# pse84 register map
Vendor: Infineon Technologies; Series: PSE84; File version: 1.0
CPU: CM33 r0p1, little endian, MPU, FPU, VTOR, 3 interrupt priority bits
Registers are 32-bit, read-write, reset 0x0 unless marked. A register's access mark holds for its fields unless they carry their own. Offsets are from the block's base; [hi:lo] are bit positions.

## MXNNLITE_2_0
Base 0x42D80000
0x04 WEIGHTSTREAMERBASEADDR
  [31:0] WEIGHTSTREAMERBASEADDR — Byte addresses, defines the address of the first dataset (first row, first col) programmable:configurable only when IP is enabled by SL_CTL bit. Do not update while a layer computation is active (BUSY_STATUS='1')! Updating during BUSY_STATUS='1' will cause unpredictable behavior.
0x08 WEIGHTSTREAMEROFFSET
  [16:0] WEIGHTSTREAMEROFFSET — Signed offset added to every weight programmable:configurable only when IP is enabled by SL_CTL bit. Do not update while a layer computation is active (BUSY_STATUS='1')! Updating during BUSY_STATUS='1' will cause unpredictable behavior.
0x0C WEIGHTSTREAMERKERNELCHANNELTIMESHEIGHTTIMESWIDTH
  [17:0] WEIGHTSTREAMERKERNELCHANNELTIMESHEIGHTTIMESWIDTH — Unsigned total number of kernel elements, disables Streamer, when last element reached. FSM updates this register as the number of nonzeroweights when sparsity is enabled, data is valid from bias streamer programmable:configurable only when IP is enabled by SL_CTL bit. Do not update while a layer computation is active (BUSY_STATUS='1')! Updating during BUSY_STATUS='1' will cause unpredictable behavior.
0x10 ACTIVATIONSTREAMERCHANNEL
  [16:0] ACTIVATIONSTREAMERCHANNEL — Unsigned number of elements in activation map per channel programmable:configurable only when IP is enabled by SL_CTL bit. Do not update while a layer computation is active (BUSY_STATUS='1')! Updating during BUSY_STATUS='1' will cause unpredictable behavior.
0x14 ACTIVATIONSTREAMERBASEADDR
  [31:0] ACTIVATIONSTREAMERBASEADDR — Byte addresses, defines the address of the first dataset (first row, first col) programmable:configurable only when IP is enabled by SL_CTL bit. Do not update while a layer computation is active (BUSY_STATUS='1')! Updating during BUSY_STATUS='1' will cause unpredictable behavior.
0x18 ACTIVATIONSTREAMEROFFSET
  [16:0] ACTIVATIONSTREAMEROFFSET — 9-bit or 17-bit signed offset added to fetch data programmable:configurable only when IP is enabled by SL_CTL bit. Do not update while a layer computation is active (BUSY_STATUS='1')! Updating during BUSY_STATUS='1' will cause unpredictable behavior.
0x1C ACTIVATIONSTREAMERKERNELCHANNELTIMESWIDTH
  [17:0] ACTIVATIONSTREAMERKERNELCHANNELTIMESWIDTH — Kernel channel times width (input assumed to be 2D row-minor or row/channel minor memory layout) programmable:configurable only when IP is enabled by SL_CTL bit. Do not update while a layer computation is active (BUSY_STATUS='1')! Updating during BUSY_STATUS='1' will cause unpredictable behavior.
0x20 ACTIVATIONSTREAMERKERNELHEIGHT
  [16:0] ACTIVATIONSTREAMERKERNELHEIGHT — Kernel height (input assumed to be 2D row-minor or row/channel minor memory layout) programmable:configurable only when IP is enabled by SL_CTL bit. Do not update while a layer computation is active (BUSY_STATUS='1')! Updating during BUSY_STATUS='1' will cause unpredictable behavior.
0x24 ACTIVATIONSTREAMERREPEATS
  [17:0] ACTIVATIONSTREAMERREPEATS — Numer of repeated fetches of kernel footprint in memory ( 1 will fetch once, 0 is invalid input) programmable:configurable only when IP is enabled by SL_CTL bit. Do not update while a layer computation is active (BUSY_STATUS='1')! Updating during BUSY_STATUS='1' will cause unpredictable behavior.
0x28 ACTIVATIONSTREAMERSTARTCOL
  [17:0] ACTIVATIONSTREAMERSTARTCOL — Signed start column to move kernel window over the activation map (col=0 & row=0 hits baseaddr) programmable:configurable only when IP is enabled by SL_CTL bit. Do not update while a layer computation is active (BUSY_STATUS='1')! Updating during BUSY_STATUS='1' will cause unpredictable behavior.
0x2C ACTIVATIONSTREAMERSTARTROW
  [17:0] ACTIVATIONSTREAMERSTARTROW — Signed start row to move kernel window over the activation map (col=0 & row=0 hits baseaddr) programmable:configurable only when IP is enabled by SL_CTL bit. Do not update while a layer computation is active (BUSY_STATUS='1')! Updating during BUSY_STATUS='1' will cause unpredictable behavior.
0x30 ACTIVATIONSTREAMERCHANNELTIMESWIDTH
  [16:0] ACTIVATIONSTREAMERCHANNELTIMESWIDTH — Unsigned number of elements in activation map per channel * width programmable:configurable only when IP is enabled by SL_CTL bit. Do not update while a layer computation is active (BUSY_STATUS='1')! Updating during BUSY_STATUS='1' will cause unpredictable behavior.
0x34 ACTIVATIONSTREAMERHEIGHT
  [16:0] ACTIVATIONSTREAMERHEIGHT — Unsigned number of elements in height in activation map till end of loop programmable:configurable only when IP is enabled by SL_CTL bit. Do not update while a layer computation is active (BUSY_STATUS='1')! Updating during BUSY_STATUS='1' will cause unpredictable behavior.
0x38 ACTIVATIONSTREAMERPADDING
  [15:0] ACTIVATIONSTREAMERPADVALUE — Defines signed values out of activation map programmable:configurable only when IP is enabled by SL_CTL bit. Do not update while a layer computation is active (BUSY_STATUS='1')! Updating during BUSY_STATUS='1' will cause unpredictable behavior.
0x3C ACTIVATIONSTREAMERSPARSITYMAPBASEADDR
  [31:0] ACTIVATIONSTREAMERSPARSITYMAPBASEADDR — Byte addresses, defines the address of start of sparsity bit(map) for sparse footprint fetch programmable:configurable only when IP is enabled by SL_CTL bit. Do not update while a layer computation is active (BUSY_STATUS='1')! Updating during BUSY_STATUS='1' will cause unpredictable behavior.
0x40 OUTSTREAMERBASEADDR
  [31:0] OUTSTREAMERBASEADDR — Byte addresses, defines the address of the first dataset (first row, first col) programmable:configurable only when IP is enabled by SL_CTL bit. Do not update while a layer computation is active (BUSY_STATUS='1')! Updating during BUSY_STATUS='1' will cause unpredictable behavior.
0x44 OUTSTREAMEROUTPUTOFFSET
  [16:0] OUTSTREAMEROUTPUTOFFSET — Signed offset added to the output activation. The outstreamer supports 8-bit output neuron. The configuration range is [-256, 255] programmable:configurable only when IP is enabled by SL_CTL bit. Do not update while a layer computation is active (BUSY_STATUS='1')! Updating during BUSY_STATUS='1' will cause unpredictable behavior.
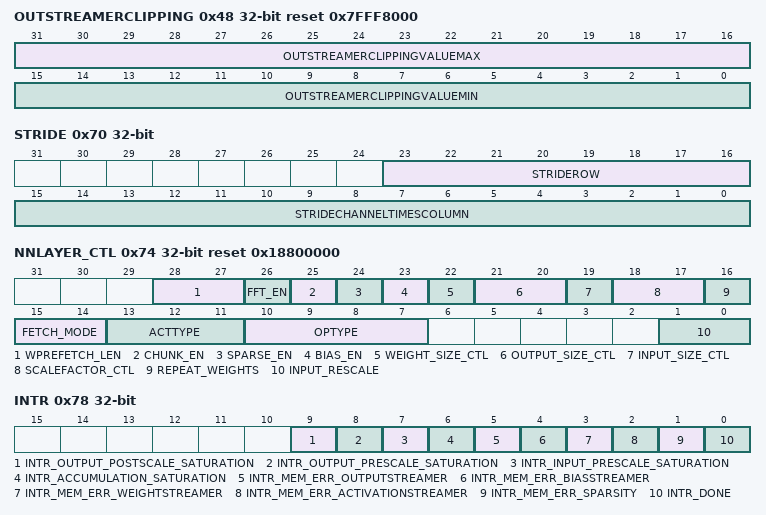
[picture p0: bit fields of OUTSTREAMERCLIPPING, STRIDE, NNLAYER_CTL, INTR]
0x48 OUTSTREAMERCLIPPING reset 0x7FFF8000
  [31:16] OUTSTREAMERCLIPPINGVALUEMAX — The maximum value (signed) to clip to, [Default is 0x7FFF] programmable:configurable only when IP is enabled by SL_CTL bit. Do not update while a layer computation is active (BUSY_STATUS='1')! Updating during BUSY_STATUS='1' will cause unpredictable behavior.
  [15:0] OUTSTREAMERCLIPPINGVALUEMIN — The minimum value (signed) to clip to [Default is 0x8000] programmable:configurable only when IP is enabled by SL_CTL bit. Do not update while a layer computation is active (BUSY_STATUS='1')! Updating during BUSY_STATUS='1' will cause unpredictable behavior.
0x4C INTERPOLATIONLUTDATA0 reset 0x3F800000
  [31:0] INTERPOLATIONLUTDATA0 — Scales the output of activation function by scaling factor a IEEE-754 single precision value [Default is set to 0x3f800000 -> 1.0] (multi-purpose output post-scaling factor. note: used only for positive outputs in piece-wise linear activation function). Name is kept from mxnnlite.1, the register has nothing to do with LUT. programmable:configurable only when IP is enabled by SL_CTL bit. Do not update while a layer computation is active (BUSY_STATUS='1')! Updating during BUSY_STATUS='1' will cause unpredictable behavior.
0x50 INTERPOLATIONLUTDATA1 reset 0x3F800000
  [31:0] INTERPOLATIONLUTDATA1 — Scales the output of activation function by scaling factor a IEEE-754 single precision value [Default is set to 0x3f800000 -> 1.0] (used only for scaling negative outputs, only needed for piece-wise linear activation function). Name is kept from mxnnlite.1, the register has nothing to do with LUT. programmable:configurable only when IP is enabled by SL_CTL bit. Do not update while a layer computation is active (BUSY_STATUS='1')! Updating during BUSY_STATUS='1' will cause unpredictable behavior.
0x54 BIASBASEADDR
  [31:0] BIASBASEADDR — Word aligned addresses, defines the address of the bias. Bias is 32 bits. programmable:configurable only when IP is enabled by SL_CTL bit. Do not update while a layer computation is active (BUSY_STATUS='1')! Updating during BUSY_STATUS='1' will cause unpredictable behavior.
0x58 SCALINGFACTORBASEADDR
  [31:0] SCALINGFACTORBASEADDR — Word aligned addresses, defines the address of the scaling factor. Scaling factor is 32 bits. programmable:configurable only when IP is enabled by SL_CTL bit. Do not update while a layer computation is active (BUSY_STATUS='1')! Updating during BUSY_STATUS='1' will cause unpredictable behavior.
0x5C NONZEROWEIGHTSPOINTER — Memory address, which stores the number of the non-zero weights
  [31:0] NONZEROWEIGHTSPOINTER — Memory address, which stores the number of the non-zero weights. It is half-word aligned. The non-zero weights size is 16 bits. programmable:configurable only when IP is enabled by SL_CTL bit. Do not update while a layer computation is active (BUSY_STATUS='1')! Updating during BUSY_STATUS='1' will cause unpredictable behavior.
0x60 INPUTRESCALINGFACTOR reset 0x3F800000 — Floating point value (IEEE-754 single precision) which scales the activation/weight input
  [31:0] INPUTRESCALINGFACTOR — Floating point value (IEEE-754 single precision) which scales the activation/weight input (when NNLAYER_CTL.INPUT_RESCALE configured) Default value: 0x3f800000 (1.0). programmable:configurable only when IP is enabled by SL_CTL bit. Do not update while a layer computation is active (BUSY_STATUS='1')! Updating during BUSY_STATUS='1' will cause unpredictable behavior.
0x64 OUTPUTCHANNELS — Unsigned number of output channels for depthwise operations
  [16:0] OUTPUTCHANNELS — Unsigned number of output channels for depthwise operations programmable:configurable only when IP is enabled by SL_CTL bit. Do not update while a layer computation is active (BUSY_STATUS='1')! Updating during BUSY_STATUS='1' will cause unpredictable behavior.
0x68 OUTPUTWIDTH — Output width for one layer
  [16:0] OUTPUTWIDTH — Output width for one layer programmable:configurable only when IP is enabled by SL_CTL bit. Do not update while a layer computation is active (BUSY_STATUS='1')! Updating during BUSY_STATUS='1' will cause unpredictable behavior.
0x6C OUTPUTHEIGHT — Output height for one layer
  [16:0] OUTPUTHEIGHT — Output height for one layer programmable:configurable only when IP is enabled by SL_CTL bit. Do not update while a layer computation is active (BUSY_STATUS='1')! Updating during BUSY_STATUS='1' will cause unpredictable behavior.
0x70 STRIDE — Stride control register
  [23:16] STRIDEROW — Stride between rows. programmable:configurable only when IP is enabled by SL_CTL bit. Do not update while a layer computation is active (BUSY_STATUS='1')! Updating during BUSY_STATUS='1' will cause unpredictable behavior.
  [15:0] STRIDECHANNELTIMESCOLUMN — Stride on channel times columns. programmable:configurable only when IP is enabled by SL_CTL bit. Do not update while a layer computation is active (BUSY_STATUS='1')! Updating during BUSY_STATUS='1' will cause unpredictable behavior.
0x74 NNLAYER_CTL reset 0x18800000 — Configure layer pattern, activation functions, activation size, and weight size (only for DSP algorithms)
  [28:27] WPREFETCH_LEN — Length of weight prefetches (each 128-bits). Value 0: 1x128 prefetch, Value 1: 2x128 prefetches, Value 2: 3x128 prefetches, Value 3: 4x128 prefetches. Default value : 3. programmable:configurable only when IP is enabled by SL_CTL bit. Do not update while a layer computation is active (BUSY_STATUS='1')! Updating during BUSY_STATUS='1' will cause unpredictable behavior.
  [26] FFT_EN — Enable 16-bit (Q1.15) real input FFT. Value 0: Disable, Value 1: Enable. programmable:configurable only when IP is enabled by SL_CTL bit. Do not update while a layer computation is active (BUSY_STATUS='1')! Updating during BUSY_STATUS='1' will cause unpredictable behavior.
  [25] CHUNK_EN — Enable output writing in chunks. Chunk length and chunk stride is defined in OutstreamerChunk register. This field is not functional in mxnnlite.2 (programming it will not have any effect). programmable:configurable only when IP is enabled by SL_CTL bit. Do not update while a layer computation is active (BUSY_STATUS='1')! Updating during BUSY_STATUS='1' will cause unpredictable behavior.
  [24] SPARSE_EN — Enable sparse footprint fetch - fetch only footprint values for which corresponding sparsity bitmap bit is set (left-to-right, top-bottom order). programmable:configurable only when IP is enabled by SL_CTL bit. Do not update while a layer computation is active (BUSY_STATUS='1')! Updating during BUSY_STATUS='1' will cause unpredictable behavior.
  [23] BIAS_EN — Enable bias fetching from the memory. programmable:configurable only when IP is enabled by SL_CTL bit. Do not update while a layer computation is active (BUSY_STATUS='1')! Updating during BUSY_STATUS='1' will cause unpredictable behavior.
  [22] WEIGHT_SIZE_CTL — Select weight size (set only for DSP algorithms). Value 0: 8 bits, value 1: 16 bits programmable:configurable only when IP is enabled by SL_CTL bit. Do not update while a layer computation is active (BUSY_STATUS='1')! Updating during BUSY_STATUS='1' will cause unpredictable behavior.
  [21:20] OUTPUT_SIZE_CTL — Select output size. Value 0: 8 bits, value 1: 16 bits, value 2: 32 bits. programmable:configurable only when IP is enabled by SL_CTL bit. Do not update while a layer computation is active (BUSY_STATUS='1')! Updating during BUSY_STATUS='1' will cause unpredictable behavior.
  [19] INPUT_SIZE_CTL — Select input size. Value 0: 8 bits, value 1: 16 bits programmable:configurable only when IP is enabled by SL_CTL bit. Do not update while a layer computation is active (BUSY_STATUS='1')! Updating during BUSY_STATUS='1' will cause unpredictable behavior.
  [18:17] SCALEFACTOR_CTL — Scaling factor control. 0: No scaling, 1: per-tensor, 2: per-axis, 3: per-row. This field is programmable:configurable only when IP is enabled by SL_CTL bit. Do not update while a layer computation is active (BUSY_STATUS='1')! Updating during BUSY_STATUS='1' will cause unpredictable behavior.
  [16] REPEAT_WEIGHTS — Repeat weights after WeightStreamerKernelChannelTimesHeightTimesWidth fetches. 0: no weight repeating, 1: weight repeating. This field is programmable:configurable only when IP is enabled by SL_CTL bit. Do not update while a layer computation is active (BUSY_STATUS='1')! Updating during BUSY_STATUS='1' will cause unpredictable behavior.
  [15:14] FETCH_MODE — Determines the data fetching pattern in activation and weight streamers. 0: DW-striped channel activation & weights, 1: Channel-minor activation & weights, 2: DW-striped channel activation only, 3: Channel-minor activation only. This field is programmable:configurable only when IP is enabled by SL_CTL bit. Do not update while a layer computation is active (BUSY_STATUS='1')! Updating during BUSY_STATUS='1' will cause unpredictable behavior.
  [13:11] ACTTYPE — Selects the type of activation function. 0: No function applied, 1: Sigmoid, 2: Tanh, 3: Piece-Wise Linear, 4: Negative power of 2 (i.e. 2^-x, output format: Q1.31), 5: Reciprocal. This field is programmable:configurable only when IP is enabled by SL_CTL bit. Do not update while a layer computation is active (BUSY_STATUS='1')! Updating during BUSY_STATUS='1' will cause unpredictable behavior.
  [10:7] OPTYPE — Selects the type of arithmetic/relational operation. 0: No Operation, 1: Multiply&Accumulate, 2: Add&Accumulate, 3: Subtract(Act-Wgt)&Accumulate, 4: Subtract(Wgt-Act)&Accumulate, 5: Sum Activation, 6: Minimum Activation, 7: Maximum Activation, 8: Sum Activation-32 (Special 32-bit inputs, i.e. shifted versions of 16-bit inputs). This field is programmable:configurable only when IP is enabled by SL_CTL bit. Do not update while a layer computation is active (BUSY_STATUS='1')! Updating during BUSY_STATUS='1' will cause unpredictable behavior.
  [1:0] INPUT_RESCALE — Rescales the activation or weights by the configured rescaling factor. 0: No Rescaling, 1: Rescale Weights, 2: Rescale Activation. This field is programmable:configurable only when IP is enabled by SL_CTL bit. Do not update while a layer computation is active (BUSY_STATUS='1')! Updating during BUSY_STATUS='1' will cause unpredictable behavior.
0x78 INTR — Interrupt cause and clear register
  [9] INTR_OUTPUT_POSTSCALE_SATURATION — Scaling factor exponent saturation (output postscaler) causes interrupt
  [8] INTR_OUTPUT_PRESCALE_SATURATION — Scaling factor exponent saturation (output prerescaler) causes interrupt
  [7] INTR_INPUT_PRESCALE_SATURATION — Scaling factor exponent saturation (input rescaler) causes interrupt
  [6] INTR_ACCUMULATION_SATURATION — Accumulation saturation causes interrupt
  [5] INTR_MEM_ERR_OUTPUTSTREAMER — Writing output to memory causes error
  [4] INTR_MEM_ERR_BIASSTREAMER — Accessing bias from memory causes error
  [3] INTR_MEM_ERR_WEIGHTSTREAMER — Accessing weight from memory causes error
  [2] INTR_MEM_ERR_ACTIVATIONSTREAMER — Accessing activation from memory causes error
  [1] INTR_MEM_ERR_SPARSITY — Accessing sparsity from memory causes error
  [0] INTR_DONE — Once accelerator calculation for one layer is done, interrupt is caused programmable:configurable only when IP is enabled by SL_CTL bit. Clear the interrupt cause bit. Same programmable for other bitfields
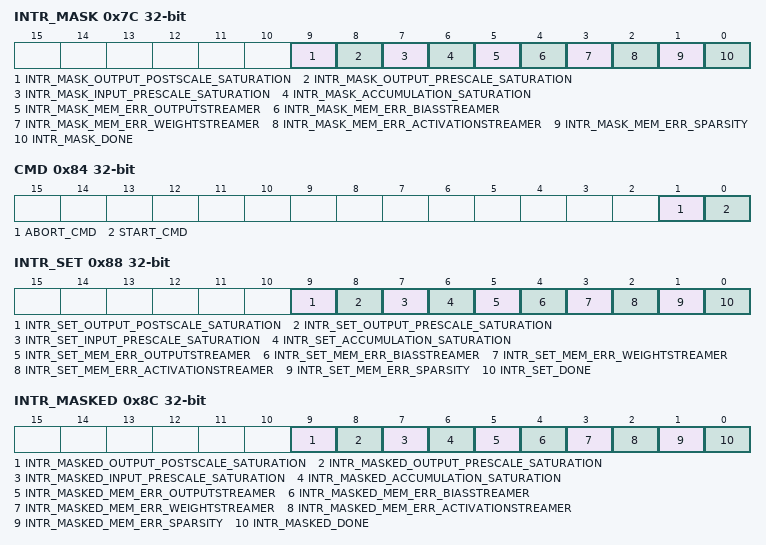
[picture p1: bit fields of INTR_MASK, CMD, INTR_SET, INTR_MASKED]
0x7C INTR_MASK — Interrupt mask register. A co-located interrupt cause bit will only cause an interrupt when its mask bit is 1
  [9] INTR_MASK_OUTPUT_POSTSCALE_SATURATION — Mask bit for scaling factor saturation (output postscaler) interrupt
  [8] INTR_MASK_OUTPUT_PRESCALE_SATURATION — Mask bit for scaling factor saturation (output prescaler) interrupt
  [7] INTR_MASK_INPUT_PRESCALE_SATURATION — Mask bit for scaling factor saturation (input rescaler) interrupt
  [6] INTR_MASK_ACCUMULATION_SATURATION — Mask bit for accumulation saturation interrupt
  [5] INTR_MASK_MEM_ERR_OUTPUTSTREAMER — Mask bit for writing output error
  [4] INTR_MASK_MEM_ERR_BIASSTREAMER — Mask bit for accessing bias error
  [3] INTR_MASK_MEM_ERR_WEIGHTSTREAMER — Mask bit for accessing weight error
  [2] INTR_MASK_MEM_ERR_ACTIVATIONSTREAMER — Mask bit for accessing activation error
  [1] INTR_MASK_MEM_ERR_SPARSITY — Mask bit for accessing sparsity error
  [0] INTR_MASK_DONE — Mask bit for calculation done for one layer to cause interrupt programmable:configurable only when IP is enabled by SL_CTL bit. Do not update while a layer computation is active (BUSY_STATUS='1')! Updating during BUSY_STATUS='1' will cause unpredictable behavior. Same programmable for other bitfields
0x80 TRIG_MASK — Trigger mask register. Calculation done for one layer triggers DataWire when its mask bit is 1
  [0] TRIG_MASK_DONE — Mask bit for calculation done for one layer to trigger DataWire programmable:configurable only when IP is enabled by SL_CTL bit. Do not update while a layer computation is active (BUSY_STATUS='1')! Updating during BUSY_STATUS='1' will cause unpredictable behavior.
0x84 CMD — Command register
  [1] ABORT_CMD — Set abort to reset all the registers programmable:configurable only when IP is enabled by SL_CTL bit.
  [0] START_CMD — Generate start pulse for the accelerator programmable:configurable only when IP is enabled by SL_CTL bit. Do not update while a layer computation is active (BUSY_STATUS='1')! Updating during BUSY_STATUS='1' will cause unpredictable behavior.
0x88 INTR_SET — Set INTR_XXX register by software for debug purpose
  [9] INTR_SET_OUTPUT_POSTSCALE_SATURATION — Set scaling factor saturation (output postscaler) interrupt
  [8] INTR_SET_OUTPUT_PRESCALE_SATURATION — Set scaling factor saturation (output prerescaler) interrupt
  [7] INTR_SET_INPUT_PRESCALE_SATURATION — Set scaling factor saturation (input rescaler) interrupt
  [6] INTR_SET_ACCUMULATION_SATURATION — Set accumulation saturation interrupt
  [5] INTR_SET_MEM_ERR_OUTPUTSTREAMER — Set writing output error
  [4] INTR_SET_MEM_ERR_BIASSTREAMER — Set accessing bias error
  [3] INTR_SET_MEM_ERR_WEIGHTSTREAMER — Set accessing weight error
  [2] INTR_SET_MEM_ERR_ACTIVATIONSTREAMER — Set accessing activation error
  [1] INTR_SET_MEM_ERR_SPARSITY — Set accessing sparsity error
  [0] INTR_SET_DONE — Set calculation done for one layer programmable:configurable only when IP is enabled by SL_CTL bit. Provides the capability to set a specific interrupt cause bit in INTR_XXX for debug purposes. Same programmable for other bitfields
0x8C INTR_MASKED ro — Virtual register for generating the interrupt signal to MCU. It is the logical AND of the INTR_XXX and INTR_MASK_XXX register
  [9] INTR_MASKED_OUTPUT_POSTSCALE_SATURATION — Masked interrupt for scaling factor (output postscaler) saturation
  [8] INTR_MASKED_OUTPUT_PRESCALE_SATURATION — Masked interrupt for scaling factor (output prescaler) saturation
  [7] INTR_MASKED_INPUT_PRESCALE_SATURATION — Masked interrupt for scaling factor (input rescaler) saturation
  [6] INTR_MASKED_ACCUMULATION_SATURATION — Masked interrupt for accumulation saturation
  [5] INTR_MASKED_MEM_ERR_OUTPUTSTREAMER — Masked interrupt for writing output error
  [4] INTR_MASKED_MEM_ERR_BIASSTREAMER — Masked interrupt for accessing bias error
  [3] INTR_MASKED_MEM_ERR_WEIGHTSTREAMER — Masked interrupt for accessing weight error
  [2] INTR_MASKED_MEM_ERR_ACTIVATIONSTREAMER — Masked interrupt for accessing activation error
  [1] INTR_MASKED_MEM_ERR_SPARSITY — Masked interrupt for accessing sparsity error
  [0] INTR_MASKED_DONE — Masked interrupt for calculation done for one layer
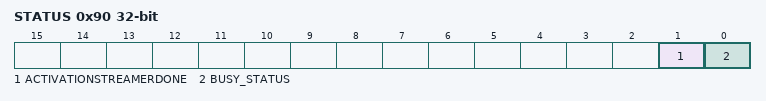
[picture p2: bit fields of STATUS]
0x90 STATUS ro
  [1] ACTIVATIONSTREAMERDONE — Indicates when last element of repeated fetch delivered
  [0] BUSY_STATUS — Indicate IP is processing. Will be high after writing START_CMD='1' until layer computation is complete or abort process is complete.
